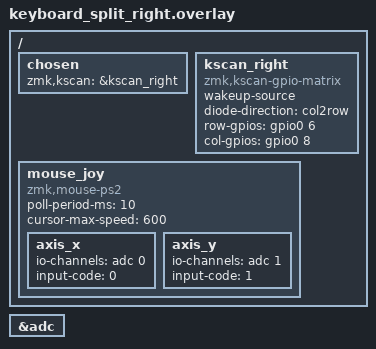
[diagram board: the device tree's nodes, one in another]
#include <dt-bindings/zmk/pointing.h>

&adc {
    status = "okay";
};

/ {
    chosen {
        zmk,kscan = &kscan_right;
    };

    kscan_right: kscan_right {
        compatible = "zmk,kscan-gpio-matrix";
        wakeup-source;
        diode-direction = "col2row";
        row-gpios = <&gpio0 6 (GPIO_ACTIVE_HIGH | GPIO_PULL_DOWN)>; 
        col-gpios = <&gpio0 8 GPIO_ACTIVE_HIGH>;
    };
/*
    right_input_listener: right_input_listener {
        compatible = "zmk,input-listener";
        device = <&mouse_joy>; 
    };
*/
    mouse_joy: mouse_joy {
        compatible = "zmk,mouse-ps2";
        poll-period-ms = <10>;
        cursor-max-speed = <600>;
        axis_x {
            io-channels = <&adc 0>;
            input-code = <0>; // REL_X
        };
        axis_y {
            io-channels = <&adc 1>;
            input-code = <1>; // REL_Y
        };
    };
};
